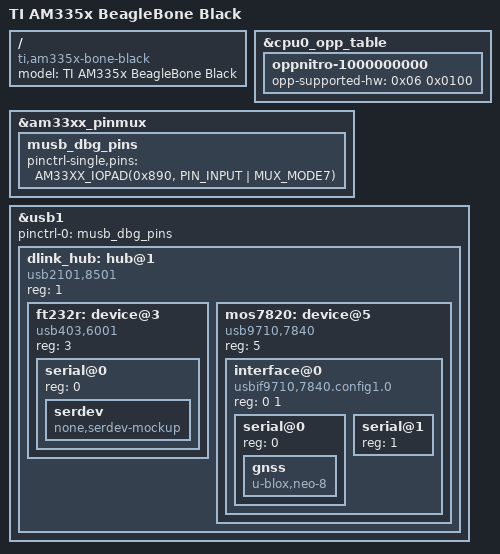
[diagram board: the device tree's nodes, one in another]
/*
 * Copyright (C) 2012 Texas Instruments Incorporated - http://www.ti.com/
 *
 * This program is free software; you can redistribute it and/or modify
 * it under the terms of the GNU General Public License version 2 as
 * published by the Free Software Foundation.
 */
/dts-v1/;

#include "am33xx.dtsi"
#include "am335x-bone-common.dtsi"
#include "am335x-boneblack-common.dtsi"

/ {
	model = "TI AM335x BeagleBone Black";
	compatible = "ti,am335x-bone-black", "ti,am335x-bone", "ti,am33xx";
};

&cpu0_opp_table {
	/*
	 * All PG 2.0 silicon may not support 1GHz but some of the early
	 * BeagleBone Blacks have PG 2.0 silicon which is guaranteed
	 * to support 1GHz OPP so enable it for PG 2.0 on this board.
	 */
	oppnitro-1000000000 {
		opp-supported-hw = <0x06 0x0100>;
	};
};

&am33xx_pinmux {
	musb_dbg_pins: musb_dbg_pins {
		pinctrl-single,pins = <
			AM33XX_IOPAD(0x890, PIN_INPUT | MUX_MODE7)
		>;
	};
};

&usb1 {
	pinctrl-names = "default";
	pinctrl-0 = <&musb_dbg_pins>;

	#address-cells = <1>;
	#size-cells = <0>;

	dlink_hub: hub@1 {
		compatible = "usb2101,8501";
		reg = <1>;

		#address-cells = <1>;
		#size-cells = <0>;

		ft232r: device@3 {
			compatible = "usb403,6001";
			reg = <3>;

			#address-cells = <1>;
			#size-cells = <0>;

			serial@0 {
				reg = <0>;

				serdev {
					compatible = "none,serdev-mockup";
				};
			};
		};

		mos7820: device@5 {
			compatible = "usb9710,7840";
			reg = <5>;

			#address-cells = <2>;
			#size-cells = <0>;

			interface@0 {
				compatible = "usbif9710,7840.config1.0";
				reg = <0 1>;

				#address-cells = <1>;
				#size-cells = <0>;

				serial@0 {
					reg = <0>;

					gnss {
						compatible = "u-blox,neo-8";
					};
				};

				serial@1 {
					reg = <1>;
				};
			};
		};
	};
};
